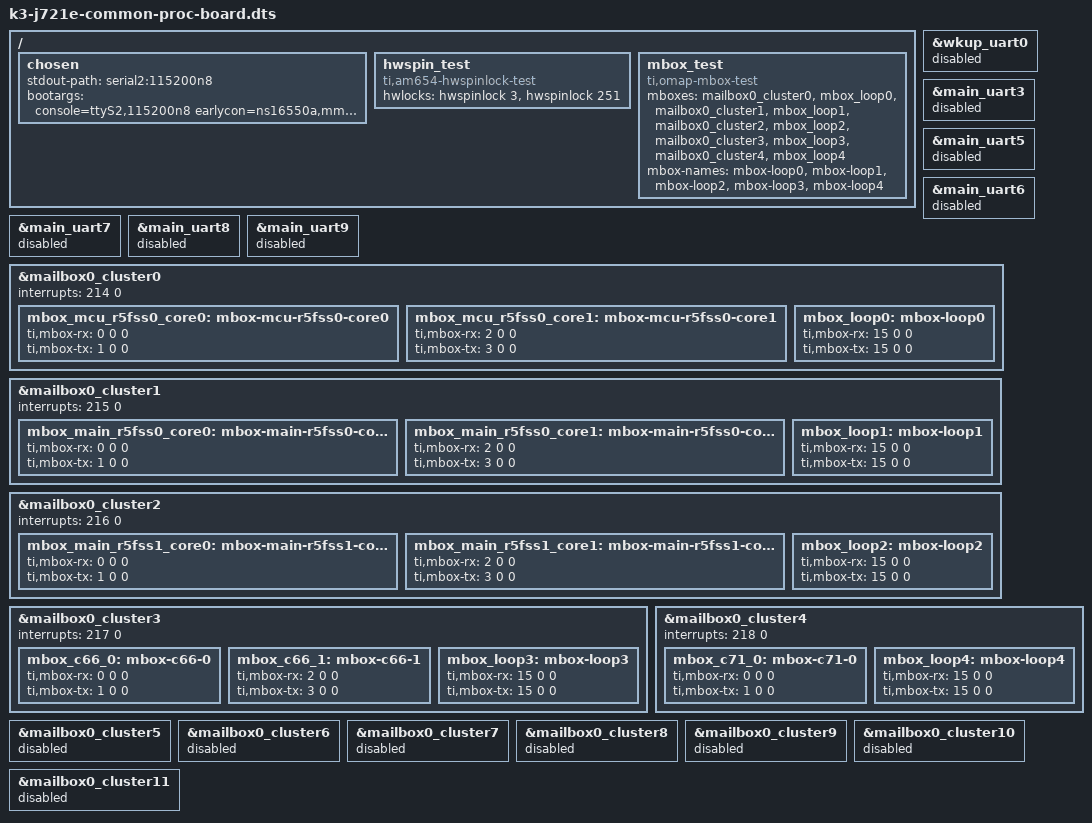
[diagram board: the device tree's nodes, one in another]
// SPDX-License-Identifier: GPL-2.0
/*
 * Copyright (C) 2019 Texas Instruments Incorporated - http://www.ti.com/
 */

/dts-v1/;

#include "k3-j721e-som-p0.dtsi"

/ {
	chosen {
		stdout-path = "serial2:115200n8";
		bootargs = "console=ttyS2,115200n8 earlycon=ns16550a,mmio32,0x02800000";
	};

	hwspin_test {
		compatible = "ti,am654-hwspinlock-test";
		hwlocks = <&hwspinlock 3>, <&hwspinlock 251>;
	};

	mbox_test {
		compatible = "ti,omap-mbox-test";
		mboxes = <&mailbox0_cluster0 &mbox_loop0>,
			 <&mailbox0_cluster1 &mbox_loop1>,
			 <&mailbox0_cluster2 &mbox_loop2>,
			 <&mailbox0_cluster3 &mbox_loop3>,
			 <&mailbox0_cluster4 &mbox_loop4>;
		mbox-names = "mbox-loop0", "mbox-loop1", "mbox-loop2",
			     "mbox-loop3", "mbox-loop4";
	};
};

&wkup_uart0 {
	/* Wakeup UART is used by System firmware */
	status = "disabled";
};

&main_uart3 {
	/* UART not brought out */
	status = "disabled";
};

&main_uart5 {
	/* UART not brought out */
	status = "disabled";
};

&main_uart6 {
	/* UART not brought out */
	status = "disabled";
};

&main_uart7 {
	/* UART not brought out */
	status = "disabled";
};

&main_uart8 {
	/* UART not brought out */
	status = "disabled";
};

&main_uart9 {
	/* UART not brought out */
	status = "disabled";
};

&mailbox0_cluster0 {
	interrupts = <214 0>;

	mbox_mcu_r5fss0_core0: mbox-mcu-r5fss0-core0 {
		ti,mbox-rx = <0 0 0>;
		ti,mbox-tx = <1 0 0>;
	};

	mbox_mcu_r5fss0_core1: mbox-mcu-r5fss0-core1 {
		ti,mbox-rx = <2 0 0>;
		ti,mbox-tx = <3 0 0>;
	};

	mbox_loop0: mbox-loop0 {
		ti,mbox-rx = <15 0 0>;
		ti,mbox-tx = <15 0 0>;
	};
};

&mailbox0_cluster1 {
	interrupts = <215 0>;

	mbox_main_r5fss0_core0: mbox-main-r5fss0-core0 {
		ti,mbox-rx = <0 0 0>;
		ti,mbox-tx = <1 0 0>;
	};

	mbox_main_r5fss0_core1: mbox-main-r5fss0-core1 {
		ti,mbox-rx = <2 0 0>;
		ti,mbox-tx = <3 0 0>;
	};

	mbox_loop1: mbox-loop1 {
		ti,mbox-rx = <15 0 0>;
		ti,mbox-tx = <15 0 0>;
	};
};

&mailbox0_cluster2 {
	interrupts = <216 0>;

	mbox_main_r5fss1_core0: mbox-main-r5fss1-core0 {
		ti,mbox-rx = <0 0 0>;
		ti,mbox-tx = <1 0 0>;
	};

	mbox_main_r5fss1_core1: mbox-main-r5fss1-core1 {
		ti,mbox-rx = <2 0 0>;
		ti,mbox-tx = <3 0 0>;
	};

	mbox_loop2: mbox-loop2 {
		ti,mbox-rx = <15 0 0>;
		ti,mbox-tx = <15 0 0>;
	};
};

&mailbox0_cluster3 {
	interrupts = <217 0>;

	mbox_c66_0: mbox-c66-0 {
		ti,mbox-rx = <0 0 0>;
		ti,mbox-tx = <1 0 0>;
	};

	mbox_c66_1: mbox-c66-1 {
		ti,mbox-rx = <2 0 0>;
		ti,mbox-tx = <3 0 0>;
	};

	mbox_loop3: mbox-loop3 {
		ti,mbox-rx = <15 0 0>;
		ti,mbox-tx = <15 0 0>;
	};
};

&mailbox0_cluster4 {
	interrupts = <218 0>;

	mbox_c71_0: mbox-c71-0 {
		ti,mbox-rx = <0 0 0>;
		ti,mbox-tx = <1 0 0>;
	};

	mbox_loop4: mbox-loop4 {
		ti,mbox-rx = <15 0 0>;
		ti,mbox-tx = <15 0 0>;
	};
};

&mailbox0_cluster5 {
	status = "disabled";
};

&mailbox0_cluster6 {
	status = "disabled";
};

&mailbox0_cluster7 {
	status = "disabled";
};

&mailbox0_cluster8 {
	status = "disabled";
};

&mailbox0_cluster9 {
	status = "disabled";
};

&mailbox0_cluster10 {
	status = "disabled";
};

&mailbox0_cluster11 {
	status = "disabled";
};
